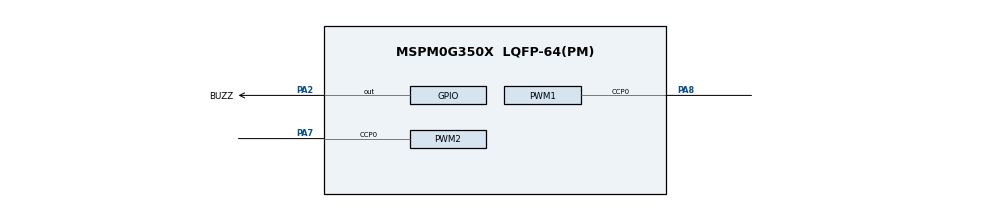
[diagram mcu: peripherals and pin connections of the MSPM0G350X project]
/**
 * These arguments were used when this file was generated. They will be automatically applied on subsequent loads
 * via the GUI or CLI. Run CLI with '--help' for additional information on how to override these arguments.
 * @cliArgs --device "MSPM0G350X" --package "LQFP-64(PM)" --part "Default" --product "mspm0_sdk@1.30.00.03"
 * @versions {"tool":"1.19.0+3426"}
 */

/**
 * Import the modules used in this configuration.
 */
const ADC12   = scripting.addModule("/ti/driverlib/ADC12", {}, false);
const ADC121  = ADC12.addInstance();
const GPIO    = scripting.addModule("/ti/driverlib/GPIO", {}, false);
const GPIO1   = GPIO.addInstance();
const PWM     = scripting.addModule("/ti/driverlib/PWM", {}, false);
const PWM1    = PWM.addInstance();
const PWM2    = PWM.addInstance();
const SYSCTL  = scripting.addModule("/ti/driverlib/SYSCTL");
const SYSTICK = scripting.addModule("/ti/driverlib/SYSTICK");
const TIMER   = scripting.addModule("/ti/driverlib/TIMER", {}, false);
const TIMER1  = TIMER.addInstance();
const TIMER2  = TIMER.addInstance();
const UART    = scripting.addModule("/ti/driverlib/UART", {}, false);
const UART1   = UART.addInstance();

/**
 * Write custom configuration values to the imported modules.
 */
const divider6       = system.clockTree["PLL_CLK2X_DIV"];
divider6.divideValue = 4;

const divider7       = system.clockTree["PLL_PDIV"];
divider7.divideValue = 2;

const divider9       = system.clockTree["UDIV"];
divider9.divideValue = 2;

const multiplier2         = system.clockTree["PLL_QDIV"];
multiplier2.multiplyValue = 10;

const mux6       = system.clockTree["FCCSELCLKMUX"];
mux6.inputSelect = "FCCSELCLKMUX_HFCLK";

const mux8       = system.clockTree["HSCLKMUX"];
mux8.inputSelect = "HSCLKMUX_SYSPLL2X";

ADC121.$name                             = "ADC_BUTTON";
ADC121.sampClkDiv                        = "DL_ADC12_CLOCK_DIVIDE_8";
ADC121.enabledInterrupts                 = ["DL_ADC12_INTERRUPT_MEM0_RESULT_LOADED"];
ADC121.sampleTime0                       = "5 ms";
ADC121.peripheral.$assign                = "ADC0";
ADC121.adcPin0Config.hideOutputInversion = scripting.forceWrite(false);
ADC121.adcPin0Config.$name               = "ti_driverlib_gpio_GPIOPinGeneric8";

const Board = scripting.addModule("/ti/driverlib/Board", {}, false);

GPIO1.$name                              = "REMINDER";
GPIO1.associatedPins.create(2);
GPIO1.associatedPins[0].$name            = "LED";
GPIO1.associatedPins[0].assignedPort     = "PORTA";
GPIO1.associatedPins[0].assignedPin      = "14";
GPIO1.associatedPins[1].$name            = "BUZZ";
GPIO1.associatedPins[1].ioStructure      = "SD";
GPIO1.associatedPins[1].internalResistor = "PULL_UP";
GPIO1.associatedPins[1].pin.$assign      = "PA2";

PWM1.clockDivider                       = 8;
PWM1.clockPrescale                      = 4;
PWM1.timerCount                         = 50000;
PWM1.pwmMode                            = "EDGE_ALIGN_UP";
PWM1.timerStartTimer                    = true;
PWM1.$name                              = "PWM_SERVO_DOWN";
PWM1.ccIndex                            = [0];
PWM1.peripheral.$assign                 = "TIMA0";
PWM1.peripheral.ccp0Pin.$assign         = "PA8";
PWM1.PWM_CHANNEL_0.$name                = "ti_driverlib_pwm_PWMTimerCC0";
PWM1.ccp0PinConfig.direction            = scripting.forceWrite("OUTPUT");
PWM1.ccp0PinConfig.hideOutputInversion  = scripting.forceWrite(false);
PWM1.ccp0PinConfig.onlyInternalResistor = scripting.forceWrite(false);
PWM1.ccp0PinConfig.passedPeripheralType = scripting.forceWrite("Digital");
PWM1.ccp0PinConfig.$name                = "ti_driverlib_gpio_GPIOPinGeneric0";

PWM2.clockDivider                       = 8;
PWM2.clockPrescale                      = 4;
PWM2.pwmMode                            = "EDGE_ALIGN_UP";
PWM2.timerStartTimer                    = true;
PWM2.$name                              = "PWM_SERVO_UP";
PWM2.ccIndex                            = [0];
PWM2.timerCount                         = 25000;
PWM2.peripheral.ccp0Pin.$assign         = "PA7";
PWM2.PWM_CHANNEL_0.$name                = "ti_driverlib_pwm_PWMTimerCC0_COPY";
PWM2.ccp0PinConfig.direction            = scripting.forceWrite("OUTPUT");
PWM2.ccp0PinConfig.hideOutputInversion  = scripting.forceWrite(false);
PWM2.ccp0PinConfig.onlyInternalResistor = scripting.forceWrite(false);
PWM2.ccp0PinConfig.passedPeripheralType = scripting.forceWrite("Digital");
PWM2.ccp0PinConfig.$name                = "ti_driverlib_gpio_GPIOPinGeneric0_COPY";

SYSCTL.clockTreeEn           = true;
SYSCTL.forceDefaultClkConfig = true;

SYSTICK.periodEnable      = true;
SYSTICK.interruptEnable   = true;
SYSTICK.systickEnable     = true;
SYSTICK.interruptPriority = "0";
SYSTICK.period            = 80;

TIMER1.timerMode         = "PERIODIC";
TIMER1.interrupts        = ["ZERO"];
TIMER1.interruptPriority = "0";
TIMER1.timerStartTimer   = true;
TIMER1.timerClkDiv       = 8;
TIMER1.$name             = "PID_TIMER";
TIMER1.timerClkPrescale  = 100;
TIMER1.timerPeriod       = "120 ms";

TIMER2.$name            = "ADC_BUTTON_TIMER";
TIMER2.timerClkDiv      = 8;
TIMER2.timerClkPrescale = 100;
TIMER2.timerMode        = "PERIODIC";
TIMER2.timerStartTimer  = true;
TIMER2.interrupts       = ["ZERO"];
TIMER2.timerPeriod      = "10 ms";

UART1.$name             = "UART_0";
UART1.rxFifoThreshold   = "DL_UART_RX_FIFO_LEVEL_ONE_ENTRY";
UART1.txFifoThreshold   = "DL_UART_TX_FIFO_LEVEL_ONE_ENTRY";
UART1.enabledInterrupts = ["RX"];
UART1.enableFIFO        = true;
UART1.txPinConfig.$name = "ti_driverlib_gpio_GPIOPinGeneric2";
UART1.rxPinConfig.$name = "ti_driverlib_gpio_GPIOPinGeneric3";

/**
 * Pinmux solution for unlocked pins/peripherals. This ensures that minor changes to the automatic solver in a future
 * version of the tool will not impact the pinmux you originally saw.  These lines can be completely deleted in order to
 * re-solve from scratch.
 */
ADC121.peripheral.adcPin0.$suggestSolution   = "PA27";
Board.peripheral.$suggestSolution            = "DEBUGSS";
Board.peripheral.swclkPin.$suggestSolution   = "PA20";
Board.peripheral.swdioPin.$suggestSolution   = "PA19";
GPIO1.associatedPins[0].pin.$suggestSolution = "PA14";
PWM2.peripheral.$suggestSolution             = "TIMG8";
TIMER1.peripheral.$suggestSolution           = "TIMG0";
TIMER2.peripheral.$suggestSolution           = "TIMA1";
UART1.peripheral.$suggestSolution            = "UART0";
UART1.peripheral.rxPin.$suggestSolution      = "PA1";
UART1.peripheral.txPin.$suggestSolution      = "PA0";
